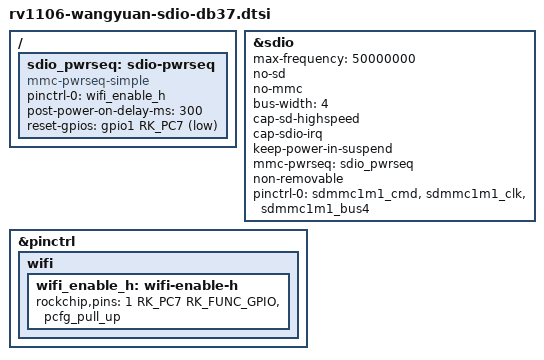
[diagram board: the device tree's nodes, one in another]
// SPDX-License-Identifier: (GPL-2.0+ OR MIT)
/*
 * Copyright (c) 2024 Guangzhou EASY EAI Technology Co., Ltd.
 */

/ {
	sdio_pwrseq: sdio-pwrseq {
		compatible = "mmc-pwrseq-simple";
		pinctrl-names = "default";
		pinctrl-0 = <&wifi_enable_h>;

		/*
		* On the module itself this is one of these (depending
		* on the actual card populated):
		* - SDIO_RESET_L_WL_REG_ON
		* - PDN (power down when low)
		*/
		post-power-on-delay-ms = <300>;
		reset-gpios = <&gpio1 RK_PC7 GPIO_ACTIVE_LOW>;
	};
};

&sdio {
	max-frequency = <50000000>;
	no-sd;
	no-mmc;
	bus-width = <4>;
	cap-sd-highspeed;
	cap-sdio-irq;
	keep-power-in-suspend;
	mmc-pwrseq = <&sdio_pwrseq>;
	non-removable;
	//sd-uhs-sdr104;
	pinctrl-names = "default";
	pinctrl-0 = <&sdmmc1m1_cmd &sdmmc1m1_clk &sdmmc1m1_bus4>;
	status = "okay";
};

&pinctrl {
	wifi {
		/omit-if-no-ref/
		wifi_enable_h: wifi-enable-h {
			rockchip,pins = <1 RK_PC7 RK_FUNC_GPIO &pcfg_pull_up>;
		};
	};
};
